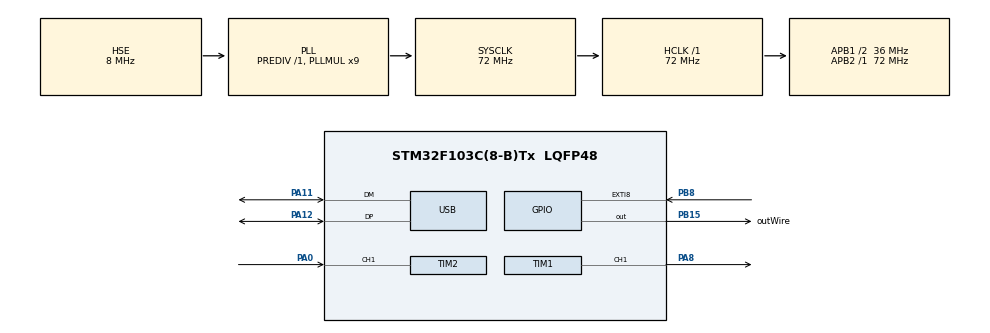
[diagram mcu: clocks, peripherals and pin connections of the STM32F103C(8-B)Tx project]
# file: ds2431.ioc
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Dma.Request0=TIM2_CH2/CH4
Dma.Request1=TIM1_UP
Dma.TIM1_UP.1.Direction=DMA_MEMORY_TO_PERIPH
Dma.TIM1_UP.1.Instance=DMA1_Channel5
Dma.TIM1_UP.1.MemDataAlignment=DMA_MDATAALIGN_HALFWORD
Dma.TIM1_UP.1.MemInc=DMA_MINC_ENABLE
Dma.TIM1_UP.1.Mode=DMA_NORMAL
Dma.TIM1_UP.1.PeriphDataAlignment=DMA_PDATAALIGN_HALFWORD
Dma.TIM1_UP.1.PeriphInc=DMA_PINC_DISABLE
Dma.TIM1_UP.1.Priority=DMA_PRIORITY_LOW
Dma.TIM2_CH2/CH4.0.Direction=DMA_PERIPH_TO_MEMORY
Dma.TIM2_CH2/CH4.0.Instance=DMA1_Channel7
Dma.TIM2_CH2/CH4.0.MemDataAlignment=DMA_MDATAALIGN_HALFWORD
Dma.TIM2_CH2/CH4.0.MemInc=DMA_MINC_ENABLE
Dma.TIM2_CH2/CH4.0.Mode=DMA_NORMAL
Dma.TIM2_CH2/CH4.0.PeriphDataAlignment=DMA_PDATAALIGN_HALFWORD
Dma.TIM2_CH2/CH4.0.PeriphInc=DMA_PINC_DISABLE
Dma.TIM2_CH2/CH4.0.Priority=DMA_PRIORITY_LOW
Mcu.Family=STM32F1
Mcu.Name=STM32F103C(8-B)Tx
Mcu.Package=LQFP48
NVIC.DMA1_Channel5_IRQn=true\:0\:0\:false\:false\:true\:false\:true\:true
NVIC.DMA1_Channel7_IRQn=true\:0\:0\:false\:false\:true\:false\:true\:true
NVIC.EXTI9_5_IRQn=true\:0\:0\:false\:false\:true\:true\:true\:true
NVIC.PriorityGroup=NVIC_PRIORITYGROUP_4
NVIC.TIM3_IRQn=true\:0\:0\:false\:false\:true\:true\:true\:true
NVIC.USB_LP_CAN1_RX0_IRQn=true\:0\:0\:false\:false\:true\:false\:true\:true
PA0-WKUP.Signal=S_TIM2_CH1_ETR
PA11.Mode=Device
PA11.Signal=USB_DM
PA12.Mode=Device
PA12.Signal=USB_DP
PA13.Mode=Trace_Asynchronous_SW
PA13.Signal=SYS_JTMS-SWDIO
PA14.Mode=Trace_Asynchronous_SW
PA14.Signal=SYS_JTCK-SWCLK
PA8.GPIO_ModeDefaultPP=GPIO_MODE_AF_PP
PA8.Signal=S_TIM1_CH1
PB15.GPIO_Label=outWire
PB15.GPIO_ModeDefaultOutputPP=GPIO_MODE_OUTPUT_OD
PB15.GPIO_PuPd=GPIO_PULLUP
PB15.PinState=GPIO_PIN_SET
PB15.Signal=GPIO_Output
PB3.Mode=Trace_Asynchronous_SW
PB3.Signal=SYS_JTDO-TRACESWO
PB8.Signal=GPXTI8
PD0-OSC_IN.Mode=HSE-External-Oscillator
PD0-OSC_IN.Signal=RCC_OSC_IN
PD1-OSC_OUT.Mode=HSE-External-Oscillator
PD1-OSC_OUT.Signal=RCC_OSC_OUT
ProjectManager.HeapSize=0x200
ProjectManager.StackSize=0x400
ProjectManager.TargetToolchain=Makefile
RCC.AHBFreq_Value=72000000
RCC.APB1CLKDivider=RCC_HCLK_DIV2
RCC.APB1Freq_Value=36000000
RCC.APB1TimFreq_Value=72000000
RCC.APB2Freq_Value=72000000
RCC.APB2TimFreq_Value=72000000
RCC.HCLKFreq_Value=72000000
RCC.PLLMUL=RCC_PLL_MUL9
RCC.SYSCLKFreq_VALUE=72000000
RCC.SYSCLKSource=RCC_SYSCLKSOURCE_PLLCLK
RCC.USBFreq_Value=48000000
RCC.USBPrescaler=RCC_USBCLKSOURCE_PLL_DIV1_5
SH.S_TIM1_CH1.0=TIM1_CH1,PWM Generation1 CH1
SH.S_TIM2_CH1_ETR.0=TIM2_CH1,TriggerSource_TI1FP1
SH.S_TIM2_CH1_ETR.1=TIM2_CH1,Input_Capture1_from_TI1
TIM1.AutoReloadPreload=TIM_AUTORELOAD_PRELOAD_DISABLE
TIM1.Channel-PWM\ Generation1\ CH1=TIM_CHANNEL_1
TIM1.OC1Preload_PWM=DISABLE
TIM1.OCFastMode_PWM-PWM\ Generation1\ CH1=TIM_OCFAST_ENABLE
TIM1.OCIdleState_1=TIM_OCIDLESTATE_SET
TIM1.OCMode_PWM-PWM\ Generation1\ CH1=TIM_OCMODE_PWM1
TIM1.OCPolarity_1=TIM_OCPOLARITY_HIGH
TIM1.Period=12
TIM1.Prescaler=35
TIM1.Pulse-PWM\ Generation1\ CH1=1
TIM1.TIM_MasterOutputTrigger=TIM_TRGO_RESET
TIM1.TIM_MasterSlaveMode=TIM_MASTERSLAVEMODE_DISABLE
TIM2.AutoReloadPreload=TIM_AUTORELOAD_PRELOAD_DISABLE
TIM2.Channel-Input_Capture1_from_TI1=TIM_CHANNEL_1
TIM2.Channel-Input_Capture2_from_TI1_63=TIM_CHANNEL_2
TIM2.ICPolarity_CH1=TIM_INPUTCHANNELPOLARITY_FALLING
TIM2.Period=9600
TIM2.Prescaler=35
TIM2.TIM_MasterOutputTrigger=TIM_TRGO_RESET
TIM2.TIM_MasterSlaveMode=TIM_MASTERSLAVEMODE_ENABLE
TIM3.Channel-Output\ Compare1\ No\ Output=TIM_CHANNEL_1
TIM3.Prescaler=71
USB_DEVICE.CLASS_NAME_FS=CDC
USB_DEVICE.PRODUCT_STRING_CDC_FS=DS2431 Emulator
USB_DEVICE.VirtualMode=Cdc
USB_DEVICE.VirtualModeFS=Cdc_FS
VP_TIM1_VS_ClockSourceINT.Mode=Internal
VP_TIM1_VS_ClockSourceITR.Mode=TriggerSource_ITR1
VP_TIM1_VS_ControllerModeTrigger.Mode=Trigger Mode
VP_TIM1_VS_OPM.Mode=OPM_bit
VP_TIM2_VS_ClockSourceINT.Mode=Internal
VP_TIM2_VS_ControllerModeReset.Mode=Reset Mode
VP_TIM2_VS_indirect_ch1.Mode=Input_Capture2_from_TI1_63
VP_TIM3_VS_ClockSourceINT.Mode=Internal
VP_TIM3_VS_OPM.Mode=OPM_bit
VP_TIM3_VS_no_output1.Mode=Output Compare1 No Output
VP_USB_DEVICE_VS_USB_DEVICE_CDC_FS.Mode=CDC_FS
board=custom

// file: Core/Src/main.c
/* USER CODE BEGIN Header */
/**
  ******************************************************************************
  * @file           : main.c
  * @brief          : Main program body
  ******************************************************************************
  * @attention
  *
  * Copyright (c) 2022 STMicroelectronics.
  * All rights reserved.
  *
  * This software is licensed under terms that can be found in the LICENSE file
  * in the root directory of this software component.
  * If no LICENSE file comes with this software, it is provided AS-IS.
  *
  ******************************************************************************
  */
/* USER CODE END Header */
#include "main.h"
#include "dma.h"
#include "tim.h"
#include "usb_device.h"
#include "gpio.h"

void SystemClock_Config(void);

int main(void)
{

  /* MCU Configuration--------------------------------------------------------*/

  /* Reset of all peripherals, Initializes the Flash interface and the Systick. */
  HAL_Init();

  /* Configure the system clock */
  SystemClock_Config();

  /* Initialize all configured peripherals */
  MX_GPIO_Init();
  MX_DMA_Init();

  MX_USB_DEVICE_Init();
  MX_TIM1_Init();
  MX_TIM2_Init();
  MX_TIM3_Init();

  /* Infinite loop */
  /* USER CODE BEGIN WHILE */
  uint16_t count=0;
  uint16_t byteBuffer[8]={0};

  while (1)
  {
    /* USER CODE END WHILE */

    /* USER CODE BEGIN 3 */

    //OWResetPulse(1000);
    if (OWResetPulse(10000)){
      OW_Reseive((uint32_t *)byteBuffer,sizeof(byteBuffer)/sizeof(uint16_t),10000);
      OW_Reseive((uint32_t *)byteBuffer,sizeof(byteBuffer)/sizeof(uint16_t),10000);
      OWSendByte(byteBuffer,sizeof(byteBuffer)/sizeof(uint16_t),10000);
      OWSendByte(byteBuffer,sizeof(byteBuffer)/sizeof(uint16_t),10000);
    }
  }
  /* USER CODE END 3 */
}

void SystemClock_Config(void)
{
  RCC_OscInitTypeDef RCC_OscInitStruct = {0};
  RCC_ClkInitTypeDef RCC_ClkInitStruct = {0};
  RCC_PeriphCLKInitTypeDef PeriphClkInit = {0};

  /** Initializes the RCC Oscillators according to the specified parameters
  * in the RCC_OscInitTypeDef structure.
  */
  RCC_OscInitStruct.OscillatorType = RCC_OSCILLATORTYPE_HSE;
  RCC_OscInitStruct.HSEState = RCC_HSE_ON;
  RCC_OscInitStruct.HSEPredivValue = RCC_HSE_PREDIV_DIV1;
  RCC_OscInitStruct.HSIState = RCC_HSI_ON;
  RCC_OscInitStruct.PLL.PLLState = RCC_PLL_ON;
  RCC_OscInitStruct.PLL.PLLSource = RCC_PLLSOURCE_HSE;
  RCC_OscInitStruct.PLL.PLLMUL = RCC_PLL_MUL9;
  if (HAL_RCC_OscConfig(&RCC_OscInitStruct) != HAL_OK)
  {
    Error_Handler();
  }

  /** Initializes the CPU, AHB and APB buses clocks
  */
  RCC_ClkInitStruct.ClockType = RCC_CLOCKTYPE_HCLK|RCC_CLOCKTYPE_SYSCLK
                              |RCC_CLOCKTYPE_PCLK1|RCC_CLOCKTYPE_PCLK2;
  RCC_ClkInitStruct.SYSCLKSource = RCC_SYSCLKSOURCE_PLLCLK;
  RCC_ClkInitStruct.AHBCLKDivider = RCC_SYSCLK_DIV1;
  RCC_ClkInitStruct.APB1CLKDivider = RCC_HCLK_DIV2;
  RCC_ClkInitStruct.APB2CLKDivider = RCC_HCLK_DIV1;

  if (HAL_RCC_ClockConfig(&RCC_ClkInitStruct, FLASH_LATENCY_2) != HAL_OK)
  {
    Error_Handler();
  }
  PeriphClkInit.PeriphClockSelection = RCC_PERIPHCLK_USB;
  PeriphClkInit.UsbClockSelection = RCC_USBCLKSOURCE_PLL_DIV1_5;
  if (HAL_RCCEx_PeriphCLKConfig(&PeriphClkInit) != HAL_OK)
  {
    Error_Handler();
  }
}

void Error_Handler(void)
{
  __disable_irq();
  while (1)
  {
  }
}
